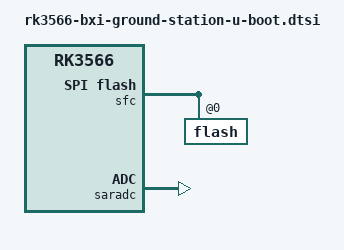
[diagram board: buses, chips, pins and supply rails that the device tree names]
// SPDX-License-Identifier: (GPL-2.0+ OR MIT)

#include "rk356x-u-boot.dtsi"

&sfc {
	flash@0 {
		bootph-pre-ram;
		bootph-some-ram;
	};
};

&saradc {
	/* ADC reference is the board's already-powered 1.8 V analog supply. */
	vdd-microvolts = <1800000>;
	status = "okay";
};
